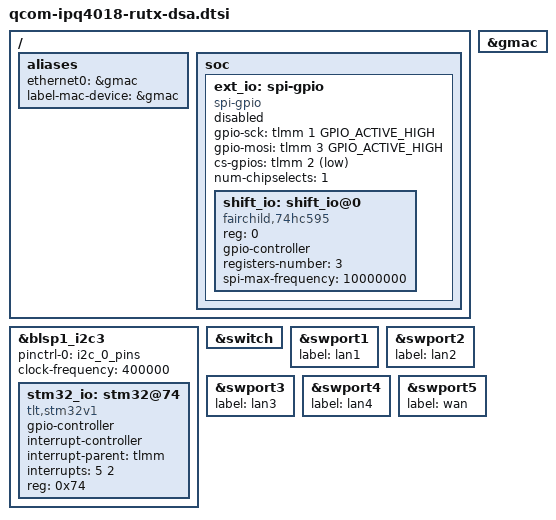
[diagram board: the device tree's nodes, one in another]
// SPDX-License-Identifier: GPL-2.0-or-later OR MIT
/*
 * Common part of the Teltonika RUTX08/09/10/11/12/14 (DSA).
 * GPIO and LED pin maps of the board DTS come from the hardware
 * description shipped in Teltonika RUTX_R_SDK_00.07.26.3.
 * A board revision drives its LEDs and modem lines either through a
 * 74HC595 chain (ext_io) or through an STM32 I/O expander (stm32_io):
 * each board DTS enables the one it uses.
 */

#include "qcom-ipq4018-rutx.dtsi"

/ {
	aliases {
		ethernet0 = &gmac;
		label-mac-device = &gmac;
	};

	soc {
		ext_io: spi-gpio {
			compatible = "spi-gpio";
			#address-cells = <1>;
			#size-cells = <0>;
			status = "disabled";

			gpio-sck = <&tlmm 1 GPIO_ACTIVE_HIGH>;
			gpio-mosi = <&tlmm 3 GPIO_ACTIVE_HIGH>;
			cs-gpios = <&tlmm 2 GPIO_ACTIVE_LOW>;
			num-chipselects = <1>;

			shift_io: shift_io@0 {
				compatible = "fairchild,74hc595";
				reg = <0>;
				gpio-controller;
				#gpio-cells = <2>;
				registers-number = <3>;
				spi-max-frequency = <10000000>;
			};
		};
	};
};

&blsp1_i2c3 {
	pinctrl-0 = <&i2c_0_pins>;
	pinctrl-names = "default";
	clock-frequency = <400000>;

	/* Driven by kmod-r2ec */
	stm32_io: stm32@74 {
		compatible = "tlt,stm32v1";
		#gpio-cells = <2>;
		#interrupt-cells = <2>;
		gpio-controller;
		interrupt-controller;
		interrupt-parent = <&tlmm>;
		interrupts = <5 2>;
		reg = <0x74>;
	};
};

&gmac {
	status = "okay";
};

&switch {
	status = "okay";
};

&swport1 {
	status = "okay";
	label = "lan1";
};

&swport2 {
	status = "okay";
	label = "lan2";
};

&swport3 {
	status = "okay";
	label = "lan3";
};

&swport4 {
	status = "okay";
	label = "lan4";
};

&swport5 {
	status = "okay";
	label = "wan";
};
